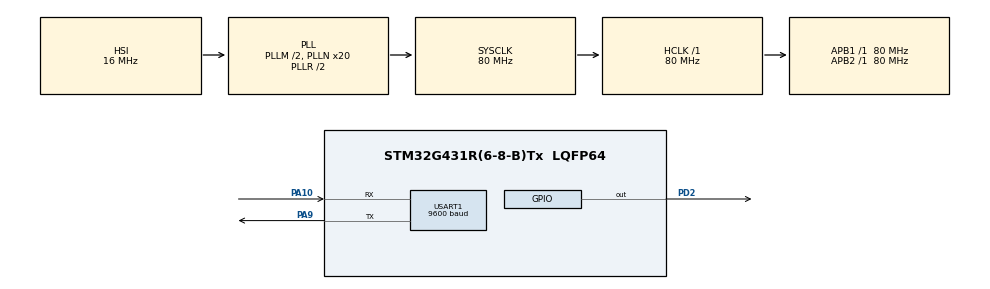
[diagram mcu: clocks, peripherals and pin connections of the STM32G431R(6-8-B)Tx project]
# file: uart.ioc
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Mcu.Family=STM32G4
Mcu.Name=STM32G431R(6-8-B)Tx
Mcu.Package=LQFP64
NVIC.PriorityGroup=NVIC_PRIORITYGROUP_4
NVIC.USART1_IRQn=true\:0\:0\:false\:false\:true\:true\:true\:true
PA10.Mode=Asynchronous
PA10.Signal=USART1_RX
PA9.GPIO_ModeDefaultPP=GPIO_MODE_AF_PP
PA9.Mode=Asynchronous
PA9.Signal=USART1_TX
PD2.Signal=GPIO_Output
PF0-OSC_IN.Mode=HSE-External-Oscillator
PF0-OSC_IN.Signal=RCC_OSC_IN
PF1-OSC_OUT.Mode=HSE-External-Oscillator
PF1-OSC_OUT.Signal=RCC_OSC_OUT
ProjectManager.HeapSize=0x200
ProjectManager.StackSize=0x400
ProjectManager.TargetToolchain=MDK-ARM V5
RCC.ADC12Freq_Value=80000000
RCC.AHBFreq_Value=80000000
RCC.APB1Freq_Value=80000000
RCC.APB1TimFreq_Value=80000000
RCC.APB2Freq_Value=80000000
RCC.APB2TimFreq_Value=80000000
RCC.CortexFreq_Value=80000000
RCC.EXTERNAL_CLOCK_VALUE=12288000
RCC.HCLKFreq_Value=80000000
RCC.HSE_VALUE=8000000
RCC.HSI48_VALUE=48000000
RCC.HSI_VALUE=16000000
RCC.LSE_VALUE=32768
RCC.PLLM=RCC_PLLM_DIV2
RCC.PLLN=20
RCC.SYSCLKFreq_VALUE=80000000
RCC.SYSCLKSource=RCC_SYSCLKSOURCE_PLLCLK
RCC.USBFreq_Value=80000000
RCC.VCOOutputFreq_Value=160000000
USART1.BaudRate=9600
USART1.RXFIFOThreshold=RXFIFO_THRESHOLD_1QUARTERFULL
USART1.TXFIFOThreshold=TXFIFO_THRESHOLD_1QUARTERFULL
USART1.VirtualMode-Asynchronous=VM_ASYNC
VP_SYS_VS_DBSignals.Mode=DisableDeadBatterySignals
board=custom

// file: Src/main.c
/* USER CODE BEGIN Header */
/**
  ******************************************************************************
  * @file           : main.c
  * @brief          : Main program body
  ******************************************************************************
  * @attention
  *
  * Copyright (c) 2024 STMicroelectronics.
  * All rights reserved.
  *
  * This software is licensed under terms that can be found in the LICENSE file
  * in the root directory of this software component.
  * If no LICENSE file comes with this software, it is provided AS-IS.
  *
  ******************************************************************************
  */
/* USER CODE END Header */
#include "main.h"
#include "usart.h"
#include "gpio.h"

void SystemClock_Config(void);

/* USER CODE BEGIN 0 */

unsigned char uart_buf[2];
unsigned char RX_buf[10];
unsigned char RX_Cont=0;
 __IO uint32_t uart_Tick=0;

void RXild_process()
{
	if(uwTick-uart_Tick<50)return;
	  uart_Tick=uwTick;
	RX_Cont=0;
	memset(RX_buf,'\0',sizeof(RX_buf));

}

/* USER CODE END 0 */

int main(void)
{

  /* MCU Configuration--------------------------------------------------------*/

  /* Reset of all peripherals, Initializes the Flash interface and the Systick. */
  HAL_Init();

  /* Configure the system clock */
  SystemClock_Config();

  /* Initialize all configured peripherals */
  MX_GPIO_Init();
  MX_USART1_UART_Init();
  /* USER CODE BEGIN 2 */
  HAL_UART_Transmit(&huart1,(unsigned char *)"hello word\r\n",sizeof("hello word\r\n")-1,50);
  printf("hello\r\n");
  printf("data:%d\"",3);

HAL_UART_Receive_IT(&huart1,uart_buf,1);
  /* USER CODE END 2 */

  /* Infinite loop */
  while (1)
  {

    /* USER CODE BEGIN 3 */

	  RXild_process();
  }
  /* USER CODE END 3 */
}

void SystemClock_Config(void)
{
  RCC_OscInitTypeDef RCC_OscInitStruct = {0};
  RCC_ClkInitTypeDef RCC_ClkInitStruct = {0};

  /** Configure the main internal regulator output voltage
  */
  HAL_PWREx_ControlVoltageScaling(PWR_REGULATOR_VOLTAGE_SCALE1);

  /** Initializes the RCC Oscillators according to the specified parameters
  * in the RCC_OscInitTypeDef structure.
  */
  RCC_OscInitStruct.OscillatorType = RCC_OSCILLATORTYPE_HSI;
  RCC_OscInitStruct.HSIState = RCC_HSI_ON;
  RCC_OscInitStruct.HSICalibrationValue = RCC_HSICALIBRATION_DEFAULT;
  RCC_OscInitStruct.PLL.PLLState = RCC_PLL_ON;
  RCC_OscInitStruct.PLL.PLLSource = RCC_PLLSOURCE_HSI;
  RCC_OscInitStruct.PLL.PLLM = RCC_PLLM_DIV2;
  RCC_OscInitStruct.PLL.PLLN = 20;
  RCC_OscInitStruct.PLL.PLLP = RCC_PLLP_DIV2;
  RCC_OscInitStruct.PLL.PLLQ = RCC_PLLQ_DIV2;
  RCC_OscInitStruct.PLL.PLLR = RCC_PLLR_DIV2;
  if (HAL_RCC_OscConfig(&RCC_OscInitStruct) != HAL_OK)
  {
    Error_Handler();
  }

  /** Initializes the CPU, AHB and APB buses clocks
  */
  RCC_ClkInitStruct.ClockType = RCC_CLOCKTYPE_HCLK|RCC_CLOCKTYPE_SYSCLK
                              |RCC_CLOCKTYPE_PCLK1|RCC_CLOCKTYPE_PCLK2;
  RCC_ClkInitStruct.SYSCLKSource = RCC_SYSCLKSOURCE_PLLCLK;
  RCC_ClkInitStruct.AHBCLKDivider = RCC_SYSCLK_DIV1;
  RCC_ClkInitStruct.APB1CLKDivider = RCC_HCLK_DIV1;
  RCC_ClkInitStruct.APB2CLKDivider = RCC_HCLK_DIV1;

  if (HAL_RCC_ClockConfig(&RCC_ClkInitStruct, FLASH_LATENCY_2) != HAL_OK)
  {
    Error_Handler();
	  HAL_UART_Receive_IT(&huart1,uart_buf,1);
  }
}

/* USER CODE BEGIN 4 */

void HAL_UART_RxCpltCallback(UART_HandleTypeDef *huart)
{

	uart_Tick=uwTick;
	 RX_buf[RX_Cont++]=uart_buf[0];
//	if(RX_Cont == 3)
//	{
//		RX_Cont=0;
//	}
	if(uart_buf[0] == '\n')
	{
		RX_Cont=0;
	}

	HAL_UART_Receive_IT(&huart1,uart_buf,1);

}

/* USER CODE END 4 */

void Error_Handler(void)
{
  __disable_irq();
  while (1)
  {
  }
}
